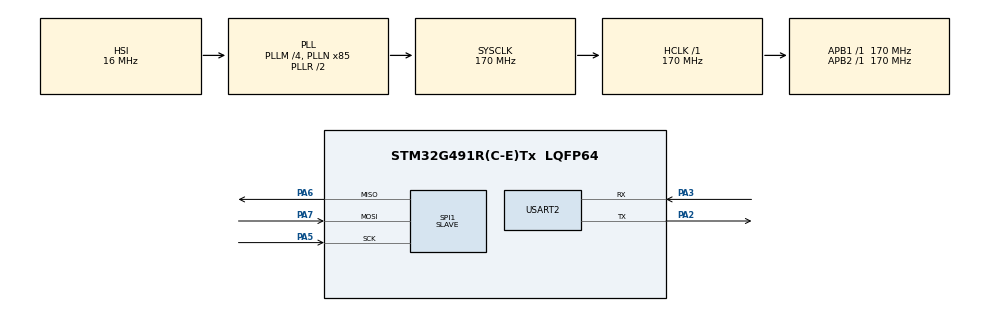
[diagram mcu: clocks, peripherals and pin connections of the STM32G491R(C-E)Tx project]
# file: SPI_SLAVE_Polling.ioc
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Mcu.Family=STM32G4
Mcu.Name=STM32G491R(C-E)Tx
Mcu.Package=LQFP64
NVIC.PriorityGroup=NVIC_PRIORITYGROUP_4
PA2.Mode=Asynchronous
PA2.Signal=USART2_TX
PA3.Mode=Asynchronous
PA3.Signal=USART2_RX
PA5.Mode=Full_Duplex_Slave
PA5.Signal=SPI1_SCK
PA6.Mode=Full_Duplex_Slave
PA6.Signal=SPI1_MISO
PA7.Mode=Full_Duplex_Slave
PA7.Signal=SPI1_MOSI
ProjectManager.HeapSize=0x200
ProjectManager.StackSize=0x400
ProjectManager.TargetToolchain=STM32CubeIDE
RCC.ADC12Freq_Value=170000000
RCC.ADC345Freq_Value=170000000
RCC.AHBFreq_Value=170000000
RCC.APB1Freq_Value=170000000
RCC.APB1TimFreq_Value=170000000
RCC.APB2Freq_Value=170000000
RCC.APB2TimFreq_Value=170000000
RCC.CortexFreq_Value=170000000
RCC.EXTERNAL_CLOCK_VALUE=12288000
RCC.HCLKFreq_Value=170000000
RCC.HSE_VALUE=24000000
RCC.HSI48_VALUE=48000000
RCC.HSI_VALUE=16000000
RCC.LSE_VALUE=32768
RCC.PLLM=RCC_PLLM_DIV4
RCC.PLLN=85
RCC.RTCClockSelection=RCC_RTCCLKSOURCE_LSE
RCC.SYSCLKFreq_VALUE=170000000
RCC.SYSCLKSource=RCC_SYSCLKSOURCE_PLLCLK
RCC.USBFreq_Value=48000000
RCC.VCOOutputFreq_Value=340000000
SPI1.DataSize=SPI_DATASIZE_8BIT
SPI1.Direction=SPI_DIRECTION_2LINES
SPI1.Mode=SPI_MODE_SLAVE
SPI1.VirtualType=VM_SLAVE
USART2.VirtualMode-Asynchronous=VM_ASYNC
VP_SYS_VS_DBSignals.Mode=DisableDeadBatterySignals
board=NUCLEO-G491RE

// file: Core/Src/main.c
/* USER CODE BEGIN Header */
/**
  ******************************************************************************
  * @file           : main.c
  * @brief          : Main program body
  ******************************************************************************
  * @attention
  *
  * Copyright (c) 2024 STMicroelectronics.
  * All rights reserved.
  *
  * This software is licensed under terms that can be found in the LICENSE file
  * in the root directory of this software component.
  * If no LICENSE file comes with this software, it is provided AS-IS.
  *
  ******************************************************************************
  */
/* USER CODE END Header */
#include "main.h"
#include "stdio.h"
#include "string.h"

SPI_HandleTypeDef hspi1;

UART_HandleTypeDef huart2;

/* USER CODE BEGIN PV */
char rx_arr[4];
//char uart_buffer[50];
/* USER CODE END PV */

void SystemClock_Config(void);
static void MX_GPIO_Init(void);
static void MX_SPI1_Init(void);
static void MX_USART2_UART_Init(void);

/* USER CODE BEGIN 0 */
int __putchar_(int ch)
{
	HAL_UART_Transmit(&huart2, (uint8_t *)&ch, 1, HAL_MAX_DELAY);
	return ch;
}
/* USER CODE END 0 */

int main(void)
{

  /* MCU Configuration--------------------------------------------------------*/

  /* Reset of all peripherals, Initializes the Flash interface and the Systick. */
  HAL_Init();

  /* Configure the system clock */
  SystemClock_Config();

  /* Initialize all configured peripherals */
  MX_GPIO_Init();
  MX_SPI1_Init();
  MX_USART2_UART_Init();

  /* Infinite loop */
  /* USER CODE BEGIN WHILE */
  while (1)
  {

	  if (HAL_SPI_Receive(&hspi1, (uint8_t *)rx_arr, sizeof(rx_arr), HAL_MAX_DELAY) == HAL_OK)
	      {
	          // Check the received data

	        	  for (uint8_t i = 0; i < sizeof(rx_arr); i++)
	        	  	      {

	        	  	          // Send the actual byte from the array
	        	  	          uint8_t ascii = rx_arr[i]+'0';
	        		 HAL_UART_Transmit(&huart2, &ascii, 1, HAL_MAX_DELAY);

	        	  	      }
//	        	  	      // Send message over UART
//	        	  	      	          //HAL_UART_Transmit(&huart2, (uint8_t *)"Data Received\n", 10, HAL_MAX_DELAY);

//	        	  int len = snprintf(uart_buffer, sizeof(uart_buffer),
//	        	                               "Received: %d %d %d %d\r\n",
//	        	                               rx_arr[0], rx_arr[1], rx_arr[2], rx_arr[3]);
//
//	        	              // Transmit the formatted string
//	        	              HAL_UART_Transmit(&huart2, (uint8_t*)uart_buffer, len, HAL_MAX_DELAY);

	        	  	      HAL_Delay(1000);

	          }
	      }
    /* USER CODE END WHILE */

  }

void SystemClock_Config(void)
{
  RCC_OscInitTypeDef RCC_OscInitStruct = {0};
  RCC_ClkInitTypeDef RCC_ClkInitStruct = {0};

  /** Configure the main internal regulator output voltage
  */
  HAL_PWREx_ControlVoltageScaling(PWR_REGULATOR_VOLTAGE_SCALE1_BOOST);

  /** Initializes the RCC Oscillators according to the specified parameters
  * in the RCC_OscInitTypeDef structure.
  */
  RCC_OscInitStruct.OscillatorType = RCC_OSCILLATORTYPE_HSI;
  RCC_OscInitStruct.HSIState = RCC_HSI_ON;
  RCC_OscInitStruct.HSICalibrationValue = RCC_HSICALIBRATION_DEFAULT;
  RCC_OscInitStruct.PLL.PLLState = RCC_PLL_ON;
  RCC_OscInitStruct.PLL.PLLSource = RCC_PLLSOURCE_HSI;
  RCC_OscInitStruct.PLL.PLLM = RCC_PLLM_DIV4;
  RCC_OscInitStruct.PLL.PLLN = 85;
  RCC_OscInitStruct.PLL.PLLP = RCC_PLLP_DIV2;
  RCC_OscInitStruct.PLL.PLLQ = RCC_PLLQ_DIV2;
  RCC_OscInitStruct.PLL.PLLR = RCC_PLLR_DIV2;
  if (HAL_RCC_OscConfig(&RCC_OscInitStruct) != HAL_OK)
  {
    Error_Handler();
  }

  /** Initializes the CPU, AHB and APB buses clocks
  */
  RCC_ClkInitStruct.ClockType = RCC_CLOCKTYPE_HCLK|RCC_CLOCKTYPE_SYSCLK
                              |RCC_CLOCKTYPE_PCLK1|RCC_CLOCKTYPE_PCLK2;
  RCC_ClkInitStruct.SYSCLKSource = RCC_SYSCLKSOURCE_PLLCLK;
  RCC_ClkInitStruct.AHBCLKDivider = RCC_SYSCLK_DIV1;
  RCC_ClkInitStruct.APB1CLKDivider = RCC_HCLK_DIV1;
  RCC_ClkInitStruct.APB2CLKDivider = RCC_HCLK_DIV1;

  if (HAL_RCC_ClockConfig(&RCC_ClkInitStruct, FLASH_LATENCY_4) != HAL_OK)
  {
    Error_Handler();
  }
}

static void MX_SPI1_Init(void)
{

  /* SPI1 parameter configuration*/
  hspi1.Instance = SPI1;
  hspi1.Init.Mode = SPI_MODE_SLAVE;
  hspi1.Init.Direction = SPI_DIRECTION_2LINES;
  hspi1.Init.DataSize = SPI_DATASIZE_8BIT;
  hspi1.Init.CLKPolarity = SPI_POLARITY_LOW;
  hspi1.Init.CLKPhase = SPI_PHASE_1EDGE;
  hspi1.Init.NSS = SPI_NSS_SOFT;
  hspi1.Init.FirstBit = SPI_FIRSTBIT_MSB;
  hspi1.Init.TIMode = SPI_TIMODE_DISABLE;
  hspi1.Init.CRCCalculation = SPI_CRCCALCULATION_DISABLE;
  hspi1.Init.CRCPolynomial = 7;
  hspi1.Init.CRCLength = SPI_CRC_LENGTH_DATASIZE;
  hspi1.Init.NSSPMode = SPI_NSS_PULSE_DISABLE;
  if (HAL_SPI_Init(&hspi1) != HAL_OK)
  {
    Error_Handler();
  }

}

static void MX_USART2_UART_Init(void)
{

  huart2.Instance = USART2;
  huart2.Init.BaudRate = 115200;
  huart2.Init.WordLength = UART_WORDLENGTH_8B;
  huart2.Init.StopBits = UART_STOPBITS_1;
  huart2.Init.Parity = UART_PARITY_NONE;
  huart2.Init.Mode = UART_MODE_TX_RX;
  huart2.Init.HwFlowCtl = UART_HWCONTROL_NONE;
  huart2.Init.OverSampling = UART_OVERSAMPLING_16;
  huart2.Init.OneBitSampling = UART_ONE_BIT_SAMPLE_DISABLE;
  huart2.Init.ClockPrescaler = UART_PRESCALER_DIV1;
  huart2.AdvancedInit.AdvFeatureInit = UART_ADVFEATURE_NO_INIT;
  if (HAL_UART_Init(&huart2) != HAL_OK)
  {
    Error_Handler();
  }
  if (HAL_UARTEx_SetTxFifoThreshold(&huart2, UART_TXFIFO_THRESHOLD_1_8) != HAL_OK)
  {
    Error_Handler();
  }
  if (HAL_UARTEx_SetRxFifoThreshold(&huart2, UART_RXFIFO_THRESHOLD_1_8) != HAL_OK)
  {
    Error_Handler();
  }
  if (HAL_UARTEx_DisableFifoMode(&huart2) != HAL_OK)
  {
    Error_Handler();
  }

}

static void MX_GPIO_Init(void)
{

  /* GPIO Ports Clock Enable */
  __HAL_RCC_GPIOA_CLK_ENABLE();

}

void Error_Handler(void)
{
  __disable_irq();
  while (1)
  {
  }
}
